# AT32A403A register map
Vendor: Keil; Series: AT32A403A; File version: 1.0
CPU: CM4 r0p1, little endian, no MPU, FPU, 4 interrupt priority bits
Registers are 32-bit, read-write, reset 0x0 unless marked. A register's access mark holds for its fields unless they carry their own. Offsets are from the block's base; [hi:lo] are bit positions; lines under a group give offsets from that group; {n}, {i} and the like mark numbered series; 'fields as' and 'values as' point back to an identical list.

## ADC2 — Analog to digital converter
Base 0x40012800
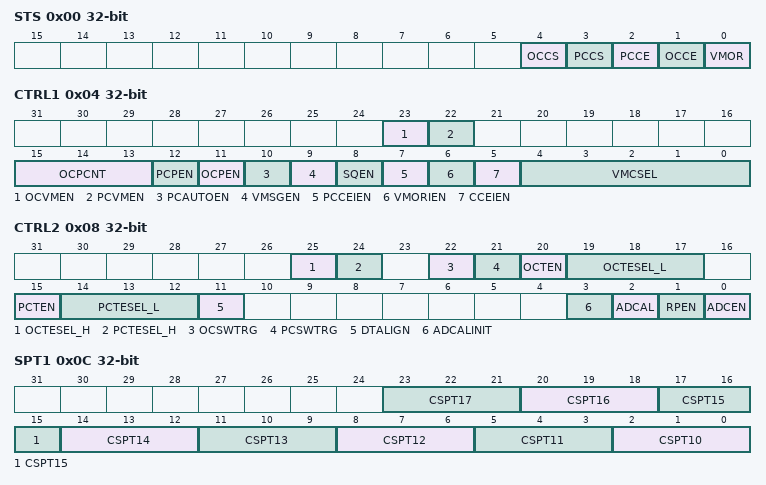
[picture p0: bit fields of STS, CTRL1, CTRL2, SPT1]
0x00 STS — status register
  [4] OCCS write-0-clears — Ordinary channel conversion start flag
    on read: 0=Idle (No channel conversion started); 1=Started (Channel conversion has started) | on write: 0=Clear flag
  [3] PCCS write-0-clears — Preempted channel conversion start flag
    values as OCCS
  [2] PCCE write-0-clears — Preempted channels conversion end flag
    on read: 0=NotComplete (Conversion is not complete); 1=Complete (Conversion is complete) | on write: 0=Clear flag
  [1] OCCE write-0-clears — Channels conversion end flag
    values as PCCE
  [0] VMOR write-0-clears — Voltage monitoring out of range flag
    on read: 0=InRange (Voltage is within the value programmed); 1=OutOfRange (Voltage is outside the value programmed) | on write: 0=Clear flag
0x04 CTRL1 — control register 1
  [23] OCVMEN — Voltage monitoring enable on ordinary channels
    on read: 0=Disabled (Voltage monitoring is disabled); 1=Enabled (Voltage monitoring is enabled) | on write: 0=Disable (Voltage monitoring disable); 1=Enable (Voltage monitoring enable)
  [22] PCVMEN — Voltage monitoring enable on preempted channels
    values as OCVMEN
  [15:13] OCPCNT — Partitioned mode conversion count of ordinary channels
  [12] PCPEN — Partitioned mode enable on preempted channels
    on read: 0=Disabled (Partitioned mode on channels is disabled); 1=Enabled (Partitioned mode on channels is enabled) | on write: 0=Disable (Partitioned mode on channels disable); 1=Enable (Partitioned mode on channels enable)
  [11] OCPEN — Partitioned mode enable on ordinary channels
    values as PCPEN
  [10] PCAUTOEN — Preempted group automatic conversion enable after ordinary group
    on read: 0=Disabled (Preempted group automatic conversion is disabled); 1=Enabled (Preempted group automatic conversion is enabled) | on write: 0=Disable (Preempted group automatic conversion disable); 1=Enable (Preempted group automatic conversion enable)
  [9] VMSGEN — Voltage monitoring enable on a single channel
    0=All (Voltage monitoring enabled on all channels); 1=Single (Voltage monitoring enabled a single channel)
  [8] SQEN — Sequence mode enable
    on read: 0=Disabled (Sequence mode is disabled); 1=Enabled (Sequence mode is enabled) | on write: 0=Disable (Sequence mode disable); 1=Enable (Sequence mode enable)
  [7] PCCEIEN — Conversion end interrupt enable for preempted channels
    on read: 0=Disabled (Channel conversion end interrupt is disabled); 1=Enabled (Channel conversion end interrupt is enabled) | on write: 0=Disable (Channel conversion end interrupt disable); 1=Enable (Channel conversion end interrupt enable)
  [6] VMORIEN — Voltage monitoring out of range interrupt enable
    on read: 0=Disabled (Voltage monitoring out of range interrupt is disabled); 1=Enabled (Voltage monitoring out of range interrupt is enabled) | on write: 0=Disable (Voltage monitoring out of range interrupt disable); 1=Enable (Voltage monitoring out of range interrupt enable)
  [5] CCEIEN — Channel conversion end interrupt enable
    values as PCCEIEN
  [4:0] VMCSEL range 0..17 — Voltage monitoring channel select
0x08 CTRL2 — control register 2
  [25] OCTESEL_H — High bit of trigger event select for ordinary channels conversion
  [24] PCTESEL_H — High bit of trigger event select for preempted channels conversion
  [22] OCSWTRG — Conversion trigger by software of ordinary channels
    0=NotTriggered (Conversion of ordinary channels not triggered); 1=Triggered (Conversion of ordinary channels triggered)
  [21] PCSWTRG — Conversion trigger by software of preempted channels
    0=NotTriggered (Conversion of preempted channels not triggered); 1=Triggered (Conversion of preempted channels triggered)
  [20] OCTEN — Trigger mode enable for ordinary channels conversion
  [19:17] OCTESEL_L — Low bit of trigger event select for ordinary channels conversion
  [15] PCTEN — Trigger mode enable for preempted channels conversion
  [14:12] PCTESEL_L — Low bit of trigger event select for preempted channels conversion
  [11] DTALIGN — Data alignment
    0=Right alignment; 1=Left alignment
  [3] ADCALINIT — initialize A/D calibration
    on read: 0=Completed (Initialization completed); 1=InProgress (Initialization is in process) | on write: 1=Init (Enable initialization)
  [2] ADCAL — A/D Calibration
    on read: 0=Completed (Calibration completed); 1=InProgress (Calibration is in process) | on write: 1=Calibrate (Enable calibration)
  [1] RPEN — Repeat mode enable
    on read: 0=Disabled (Repetition mode is disabled); 1=Enabled (Repetition mode is enabled) | on write: 0=Disable (Repetition mode disable); 1=Enable (Repetition mode enable)
  [0] ADCEN — A/D converter enable
    on read: 0=Disabled (ADC is disabled); 1=Enabled (ADC is enabled) | on write: 0=Disable (ADC disable); 1=Enable (ADC enable)
0x0C SPT1 — sample time register 1
  [3n-28:3n-30] CSPT{n} (n=10..17) — Selection sample time of channel ADC_IN{n}
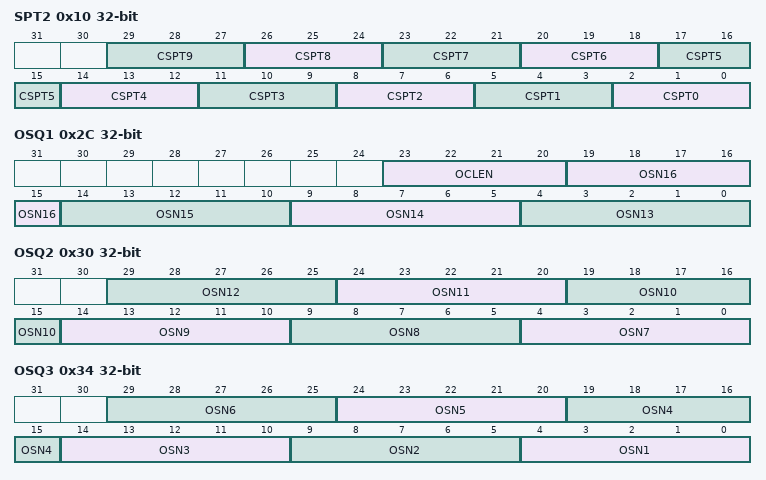
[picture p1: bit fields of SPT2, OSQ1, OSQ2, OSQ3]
0x10 SPT2 — sample time register 2
  [3n+2:3n] CSPT{n} (n=0..9) — Selection sample time of channel ADC_IN{n}
{0x10+4i} PCDTO{i} (i=1..4) — Data offset for Preempted channel {i}
  [11:0] DTO — Data offset for Preempted channel 1
0x24 VMHB reset 0xFFF — Voltage monitoring high boundary register
  [11:0] VMB — Voltage monitoring high boundary
0x28 VMLB — Voltage monitoring low boundary register
  [11:0] VMB — Voltage monitoring low boundary
0x2C OSQ1 — Ordinary sequence register 1
  [23:20] OCLEN — Ordinary conversion sequence length
  [5n-61:5n-65] OSN{n} (n=13..16) — Number of {n}th conversion in ordinary sequence
    {v}=AdcIn{v} (v=0..17)
0x30 OSQ2 — Ordinary sequence register 2
  [5n-31:5n-35] OSN{n} (n=7..12) — Number of {n}th conversion in ordinary sequence
    {v}=AdcIn{v} (v=0..17)
0x34 OSQ3 — Ordinary sequence register 3
  [5n-1:5n-5] OSN{n} (n=1..6) — Number of {n}th conversion in ordinary sequence
    {v}=AdcIn{v} (v=0..17)
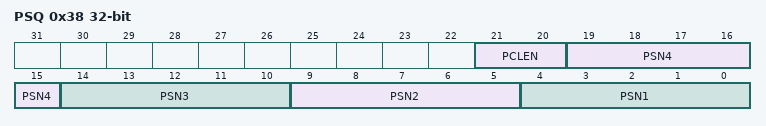
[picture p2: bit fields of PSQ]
0x38 PSQ — Preempted sequence register
  [21:20] PCLEN — Preempted conversion sequence length
  [5n-1:5n-5] PSN{n} (n=1..4) range 0..17 — Number of {n} conversion in preempted sequence
{0x38+4i} PDT{i} (i=1..4) ro — Preempted data register {i}
  [15:0] PDT — Preempted data
0x4C ODT ro — Ordinary data register
  [15:0] ODT — Conversion data of ordinary channel

## ADC3 — Analog to digital converter
Base 0x40013C00
Registers as ADC2; these are added or differ:
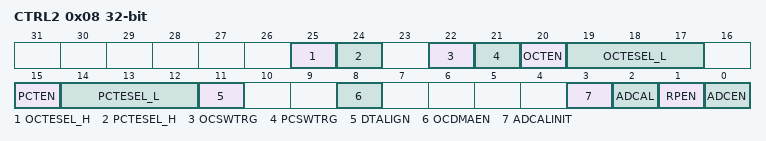
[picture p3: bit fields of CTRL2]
0x08 CTRL2 — control register 2
  [25] OCTESEL_H — High bit of trigger event select for ordinary channels conversion
  [24] PCTESEL_H — High bit of trigger event select for preempted channels conversion
  [22] OCSWTRG — Conversion trigger by software of ordinary channels
    0=NotTriggered (Conversion of ordinary channels not triggered); 1=Triggered (Conversion of ordinary channels triggered)
  [21] PCSWTRG — Conversion trigger by software of preempted channels
    0=NotTriggered (Conversion of preempted channels not triggered); 1=Triggered (Conversion of preempted channels triggered)
  [20] OCTEN — Trigger mode enable for ordinary channels conversion
  [19:17] OCTESEL_L — Low bit of trigger event select for ordinary channels conversion
  [15] PCTEN — Trigger mode enable for preempted channels conversion
  [14:12] PCTESEL_L — Low bit of trigger event select for preempted channels conversion
  [11] DTALIGN — Data alignment
    0=Right alignment; 1=Left alignment
  [8] OCDMAEN — DMA transfer enable of ordinary channels
  [3] ADCALINIT — initialize A/D calibration
    on read: 0=Completed (Initialization completed); 1=InProgress (Initialization is in process) | on write: 1=Init (Enable initialization)
  [2] ADCAL — A/D Calibration
    on read: 0=Completed (Calibration completed); 1=InProgress (Calibration is in process) | on write: 1=Calibrate (Enable calibration)
  [1] RPEN — Repeat mode enable
    on read: 0=Disabled (Repetition mode is disabled); 1=Enabled (Repetition mode is enabled) | on write: 0=Disable (Repetition mode disable); 1=Enable (Repetition mode enable)
  [0] ADCEN — A/D converter enable
    on read: 0=Disabled (ADC is disabled); 1=Enabled (ADC is enabled) | on write: 0=Disable (ADC disable); 1=Enable (ADC enable)
